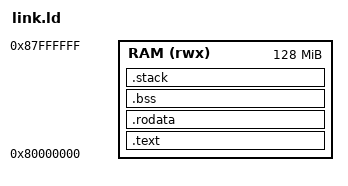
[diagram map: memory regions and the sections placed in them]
/* Карта памяти для машины virt.

   По сравнению со второй статьёй появился стек. Важно понимать, что
   это не что-то встроенное в процессор: это просто кусок памяти,
   который мы сами объявили и адрес которого сами положим в регистр sp.
   Никто, кроме нашего кода, про этот кусок не знает. */

OUTPUT_ARCH(riscv)
ENTRY(_start)

MEMORY
{
    RAM (rwx) : ORIGIN = 0x80000000, LENGTH = 128M
}

SECTIONS
{
    .text : {
        *(.text)
        *(.text.*)
    } > RAM

    .rodata : {
        *(.rodata)
        *(.rodata.*)
    } > RAM

    .bss : {
        *(.bss)
        *(.bss.*)
    } > RAM

    /* Место под стек. NOLOAD означает, что грузить туда нечего: в файле
       программы этих байтов нет, они просто резервируются в памяти.

       Стек растёт вниз, от больших адресов к меньшим, поэтому в sp
       кладут верхнюю границу, а каждый новый кадр отнимает от неё.
       Отсюда и вычитание в прологе. Направление задано не процессором,
       а psABI: в железе нет ничего, что мешало бы стеку расти вверх.

       Откуда взялся размер. Глубина рекурсии для fib(n) это ровно n
       кадров: цепочка fib(n) -> fib(n-1) -> ... -> fib(1), и базовый
       случай тоже занимает кадр, потому что пролог выполняется до
       проверки. Кадр 16 байт, значит нужно 16 * n.

       Сверху n ограничено печатью: print_dec сравнивает знаковым blt,
       так что последнее осмысленное число это fib(46) = 1836311903.
       Дальше результат выходит за знаковые 32 бита. Отсюда потолок
       46 * 16 = 736 байт. Округляем вверх, с запасом на кадры печати. */
    .stack (NOLOAD) : {
        . = ALIGN(16);
        _stack_bottom = .;
        . += 1024;
        . = ALIGN(16);
        _stack_top = .;
    } > RAM
}
